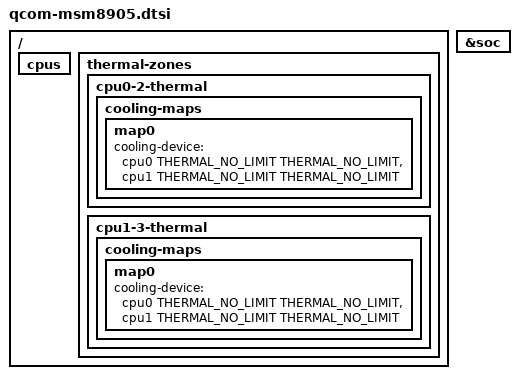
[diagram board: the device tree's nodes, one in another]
// SPDX-License-Identifier: GPL-2.0-only
#include "qcom-msm8909.dtsi"
/ {
	cpus {
		/delete-node/ cpu@2;
		/delete-node/ cpu@3;
	};
	thermal-zones {
		cpu0-2-thermal {
			cooling-maps {
				map0 {
					cooling-device = <&cpu0 THERMAL_NO_LIMIT THERMAL_NO_LIMIT>,
							 <&cpu1 THERMAL_NO_LIMIT THERMAL_NO_LIMIT>;
				};
			};
		};
		cpu1-3-thermal {
			cooling-maps {
				map0 {
					cooling-device = <&cpu0 THERMAL_NO_LIMIT THERMAL_NO_LIMIT>,
							 <&cpu1 THERMAL_NO_LIMIT THERMAL_NO_LIMIT>;
				};
			};
		};
	};
};

&soc {
	/delete-node/ power-manager@b0a8000;
	/delete-node/ power-manager@b0a9000;
	/delete-node/ power-manager@b0b8000;
	/delete-node/ power-manager@b0b9000;
};
